VERSION ""

NS_ :

BS_:

BU_: XXX

BO_ 492 EPS_STATUS: 8 XXX
 SG_ STEERING_RATE : 17|10@0+ (1,0) [0|1] "" XXX
 SG_ TORQUE_HUMAN : 3|12@0+ (1,-1024) [0|1] "Nm" XXX

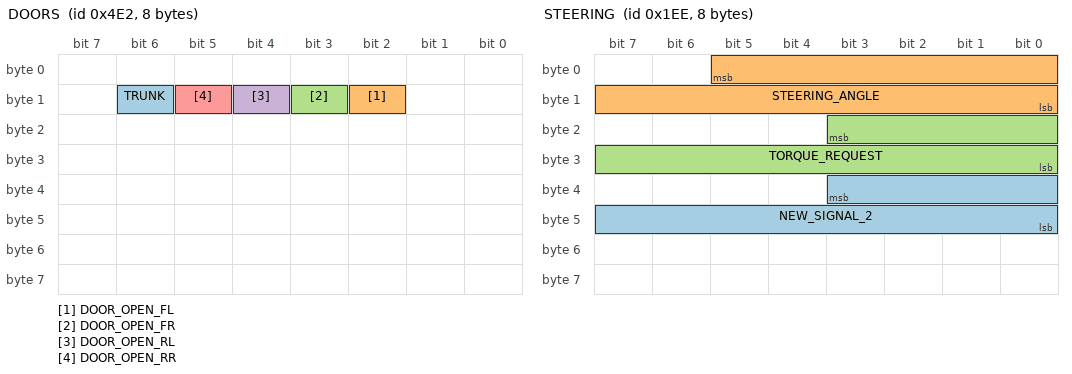
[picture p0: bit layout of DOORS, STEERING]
BO_ 1250 DOORS: 8 XXX
 SG_ TRUNK : 14|1@0+ (1,0) [0|1] "" XXX
 SG_ DOOR_OPEN_FL : 10|1@0+ (1,0) [0|1] "" XXX
 SG_ DOOR_OPEN_FR : 11|1@0+ (1,0) [0|1] "" XXX
 SG_ DOOR_OPEN_RL : 12|1@0+ (1,0) [0|1] "" XXX
 SG_ DOOR_OPEN_RR : 13|1@0+ (1,0) [0|1] "" XXX

BO_ 1262 GEAR: 8 XXX
 SG_ PRNDL : 11|4@0+ (1,0) [0|15] "" XXX

BO_ 875 SEATBELT_STATUS: 8 XXX
 SG_ SEATBELT_DRIVER_UNLATCHED : 16|1@0+ (1,0) [0|1] "" XXX

BO_ 1264 STEERING_LEVERS: 8 XXX
 SG_ TURN_SIGNALS : 3|4@0+ (1,0) [0|15] "" XXX
 SG_ HIGH_BEAM_FLASH : 15|1@0+ (1,0) [0|1] "" XXX

BO_ 480 TRACTION_BUTTON: 8 XXX
 SG_ TRACTION_OFF : 3|1@0+ (1,0) [0|1] "" XXX

BO_ 740 SPEED_1: 8 XXX
 SG_ SPEED_RIGHT : 35|12@0+ (0.00625,0) [0|1] "" XXX
 SG_ SPEED_LEFT : 19|12@0+ (0.00625,0) [0|1] "" XXX

BO_ 520 TORQUE_REQUEST: 8 XXX
 SG_ NEW_SIGNAL_2 : 19|12@0+ (1,-2048) [0|1] "" XXX
 SG_ NEW_SIGNAL_1 : 3|12@0+ (1,-2048) [0|1] "" XXX

BO_ 494 STEERING: 8 XXX
 SG_ NEW_SIGNAL_2 : 35|12@0+ (0,0) [0|1] "" XXX
 SG_ STEERING_ANGLE : 5|14@0+ (0.125,-895) [0|1] "" XXX
 SG_ TORQUE_REQUEST : 19|12@0+ (1,-2000) [0|1] "" XXX

BO_ 738 BRAKE_2: 8 XXX

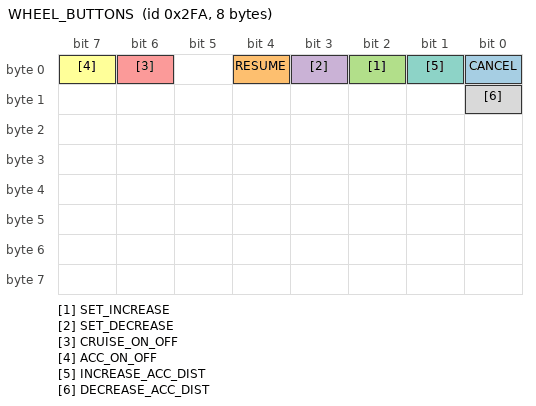
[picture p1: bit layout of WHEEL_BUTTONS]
BO_ 762 WHEEL_BUTTONS: 8 XXX
 SG_ CANCEL : 0|1@0+ (1,0) [0|1] "" XXX
 SG_ RESUME : 4|1@0+ (1,0) [0|1] "" XXX
 SG_ SET_INCREASE : 2|1@0+ (1,0) [0|1] "" XXX
 SG_ SET_DECREASE : 3|1@0+ (1,0) [0|1] "" XXX
 SG_ CRUISE_ON_OFF : 6|1@0+ (1,0) [0|1] "" XXX
 SG_ ACC_ON_OFF : 7|1@0+ (1,0) [0|1] "" XXX
 SG_ INCREASE_ACC_DIST : 1|1@0+ (1,0) [0|1] "" XXX
 SG_ DECREASE_ACC_DIST : 8|1@0+ (1,0) [0|1] "" XXX

BO_ 524 AUTO_PARK: 8 XXX

CM_ SG_ 492 TORQUE_HUMAN "0x400 is 0 degrees, pos is left, neg is right";
CM_ SG_ 1250 TRUNK "1 = open, 0 = closed";
CM_ SG_ 1250 DOOR_OPEN_FL "1 = open, 0 = closed";
CM_ SG_ 1250 DOOR_OPEN_FR "1 = open, 0 = closed";
CM_ SG_ 1250 DOOR_OPEN_RL "1 = open, 0 = closed";
CM_ SG_ 1250 DOOR_OPEN_RR "1 = open, 0 = closed";
CM_ SG_ 1262 PRNDL "1 = park, 2 = reverse, 3 = neutral, 4 = drive, 5 = sport";
CM_ SG_ 875 SEATBELT_DRIVER_UNLATCHED "1 = unlatched, 0 = safety first";
CM_ SG_ 1264 TURN_SIGNALS "0 = off, 1 = left blinker, 2 = right blinker";
CM_ SG_ 480 TRACTION_OFF "0 = TCS on, 1 = TCS off (light on dash ON)";
